# STM32H7B3x register map
File version: 2.2
CPU: CM7 r0p1, little endian, MPU, FPU, 4 interrupt priority bits
Registers are 32-bit, read-write, reset 0x0 unless marked. A register's access mark holds for its fields unless they carry their own. Offsets are from the block's base; [hi:lo] are bit positions; {n}, {i} and the like mark numbered series.

## GPIOA — GPIO
Base 0x58020000
Same registers: GPIOB 0x58020400, GPIOC 0x58020800, GPIOD 0x58020C00, GPIOE 0x58021000, GPIOF 0x58021400, GPIOG 0x58021800, GPIOH 0x58021C00, GPIOI 0x58022000, GPIOJ 0x58022400, GPIOK 0x58022800
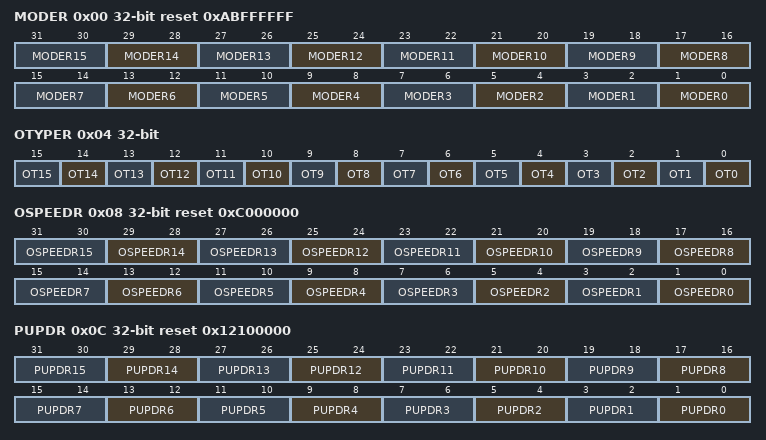
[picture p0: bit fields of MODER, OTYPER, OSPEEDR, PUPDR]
0x00 MODER reset 0xABFFFFFF — GPIO port mode register
  [all] fields
    0=Input mode (reset state); 1=Output (General purpose output mode); 2=Alternate function mode; 3=Analog mode
  [2n+1:2n] MODER{n} (n=0..15) — [1:0]: Port x configuration bits (y = 0..15) These bits are written by software to configure the I/O mode.
0x04 OTYPER — GPIO port output type register
  [all] fields
    0=PushPull (Output push-pull (reset state)); 1=OpenDrain (Output open-drain)
  [n] OT{n} (n=0..15) — Port x configuration bits (y = 0..15) These bits are written by software to configure the I/O output type.
0x08 OSPEEDR reset 0xC000000 — GPIO port output speed register
  [all] fields
    0=LowSpeed; 1=MediumSpeed; 2=HighSpeed; 3=VeryHighSpeed
  [2n+1:2n] OSPEEDR{n} (n=0..15) — [1:0]: Port x configuration bits (y = 0..15) These bits are written by software to configure the I/O output speed. Note: Refer to the device datasheet for the frequency specifications and the power supply and load conditions for each speed.
0x0C PUPDR reset 0x12100000 — GPIO port pull-up/pull-down register
  [all] fields
    0=Floating (No pull-up, pull-down); 1=PullUp; 2=PullDown
  [2n+1:2n] PUPDR{n} (n=0..15) — [1:0]: Port x configuration bits (y = 0..15) These bits are written by software to configure the I/O pull-up or pull-down
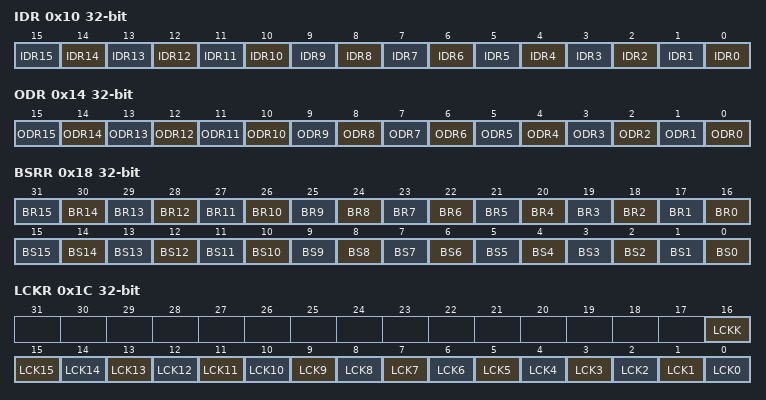
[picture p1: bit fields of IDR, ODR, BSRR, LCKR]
0x10 IDR ro — GPIO port input data register
  [all] fields
    on read: 0=Low (Input is logic low); 1=High (Input is logic high)
  [n] IDR{n} (n=0..15) — Port input data bit (y = 0..15) These bits are read-only. They contain the input value of the corresponding I/O port.
0x14 ODR — GPIO port output data register
  [all] fields
    0=Low (Set output to logic low); 1=High (Set output to logic high)
  [n] ODR{n} (n=0..15) — Port output data bit These bits can be read and written by software. Note: For atomic bit set/reset, the OD bits can be individually set and/or reset by writing to the GPIOx_BSRR or GPIOx_BRR registers (x = A..F).
0x18 BSRR wo — GPIO port bit set/reset register
  [n+16] BR{n} (n=0..15) — Port x reset bit y (y = 0..15) These bits are write-only. A read to these bits returns the value 0x0000. Note: If both BSx and BRx are set, BSx has priority.
    on write: 1=Resets the corresponding ODRx bit
  [n] BS{n} (n=0..15) — Port x set bit y (y= 0..15) These bits are write-only. A read to these bits returns the value 0x0000.
    on write: 1=Set (Sets the corresponding ODRx bit)
0x1C LCKR — This register is used to lock the configuration of the port bits when a correct write sequence is applied to bit 16 (LCKK). The value of bits [15:0] is used to lock the configuration of the GPIO. During the write sequence, the value of LCKR[15:0] must not change. When the LOCK sequence has been applied on a port bit, the value of this port bit can no longer be modified until the next MCU reset or peripheral reset.A specific write sequence is used to write to the GPIOx_LCKR register. Only word access (32-bit long) is allowed during this locking sequence.Each lock bit freezes a specific configuration register (control and alternate function registers).
  [16] LCKK — Lock key This bit can be read any time. It can only be modified using the lock key write sequence. LOCK key write sequence: WR LCKR[16] = 1 + LCKR[15:0] WR LCKR[16] = 0 + LCKR[15:0] WR LCKR[16] = 1 + LCKR[15:0] RD LCKR RD LCKR[16] = 1 (this read operation is optional but it confirms that the lock is active) Note: During the LOCK key write sequence, the value of LCK[15:0] must not change. Any error in the lock sequence aborts the lock. After the first lock sequence on any bit of the port, any read access on the LCKK bit will return 1 until the next MCU reset or peripheral reset.
    0=NotActive (Port configuration lock key not active); 1=Active (Port configuration lock key active)
  [n] LCK{n} (n=0..15) — Port x lock bit y (y= 0..15) These bits are read/write but can only be written when the LCKK bit is 0.
    0=Unlocked (Port configuration not locked); 1=Locked (Port configuration locked)
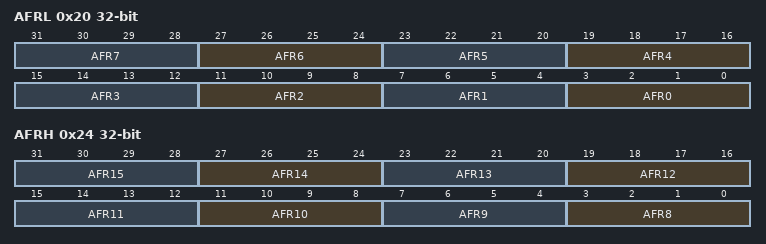
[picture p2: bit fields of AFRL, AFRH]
0x20 AFRL — GPIO alternate function low register
  [all] fields
    {v}=AF{v} (v=0..15)
  [4n+3:4n] AFR{n} (n=0..7) — [3:0]: Alternate function selection for port x pin y (y = 0..7) These bits are written by software to configure alternate function I/Os AFSELy selection:
0x24 AFRH — GPIO alternate function high register
  [all] fields
    {v}=AF{v} (v=0..15)
  [4n-29:4n-32] AFR{n} (n=8..15) — [3:0]: Alternate function selection for port x pin y (y = 8..15) These bits are written by software to configure alternate function I/Os
